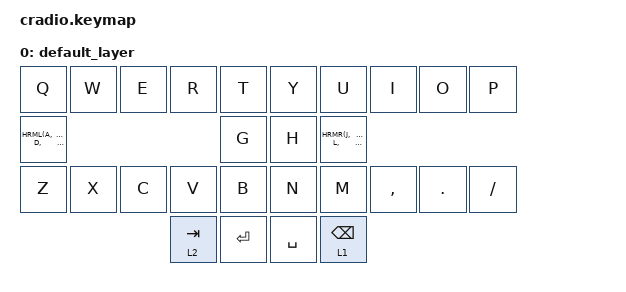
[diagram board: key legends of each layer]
// Copyright (c) 2022 The ZMK Contributors
// SPDX-License-Identifier: MIT

#include <behaviors.dtsi>
#include <dt-bindings/zmk/keys.h>
#include <dt-bindings/zmk/bt.h>

/ {

    keymap {
        compatible = "zmk,keymap";
        default_layer {
            bindings = <
        //╭──────────┬──────────┬──────────┬──────────┬──────────╮   ╭──────────┬──────────┬──────────┬──────────┬──────────╮
        //│  Q       │  W       │  E       │  R       │  T       │   │  Y       │  U       │  I       │  O       │  P       │
            &kp Q      &kp W      &kp E      &kp R      &kp T          &kp Y      &kp U      &kp I      &kp O      &kp P
        //├──────────┼──────────┼──────────┼──────────┼──────────┤   ├──────────┼──────────┼──────────┼──────────┼──────────┤
        //│  A       │  S       │  D       │  F       │  G       │   │  H       │  J       │  K       │  L       │ ' "      │
            HRML(A,        S,         D,         F)     &kp G          &kp H      HRMR(J,        K,         L,        SQT)
        //├──────────┼──────────┼──────────┼──────────┼──────────┤   ├──────────┼──────────┼──────────┼──────────┼──────────┤
        //│  Z       │  X       │  C       │  V       │  B       │   │  N       │  M       │ , <      │ . >      │ / ?      │
            &kp Z      &kp X      &kp C      &kp V      &kp B          &kp N      &kp M      &kp COMMA  &kp DOT    &kp FSLH
        //╰──────────┴──────────┴──────────┼──────────┼──────────┤   ├──────────┼──────────┼──────────┴──────────┴──────────╯
                                            &lt 2 TAB   &kp ENTER     &kp SPACE  &lt 1 BSPC
        //                                 ╰──────────┴──────────╯   ╰──────────┴──────────╯
            >;
        };
    };
};
